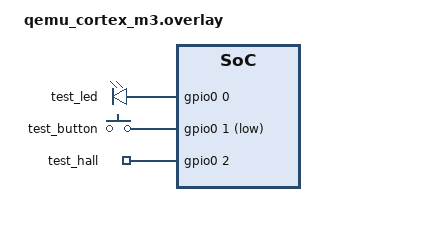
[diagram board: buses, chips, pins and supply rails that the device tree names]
#include <zephyr/dt-bindings/gpio/gpio.h>

/ {
    aliases {
        led0 = &test_led;
        sw0 = &test_button;
        hal0 = &test_hall;
    };

    leds {
        compatible = "gpio-leds";
        test_led: led_0 {
            /* Pin 0 on GPIO port 0 */
            gpios = <&gpio0 0 GPIO_ACTIVE_HIGH>;
        };
    };

    buttons {
        compatible = "gpio-keys";
        test_button: btn_0 {
            /* Pin 1 on GPIO port 0 */
            gpios = <&gpio0 1 (GPIO_PULL_UP | GPIO_ACTIVE_LOW)>;
        };
        test_hall: hall_0 {
            /* Pin 2 on GPIO port 0 */
            gpios = <&gpio0 2 GPIO_ACTIVE_HIGH>;
        };
    };
};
